AUTOSAR XML (schema 00052)
package /apd/AdaptiveApplicationSwComponentTypes
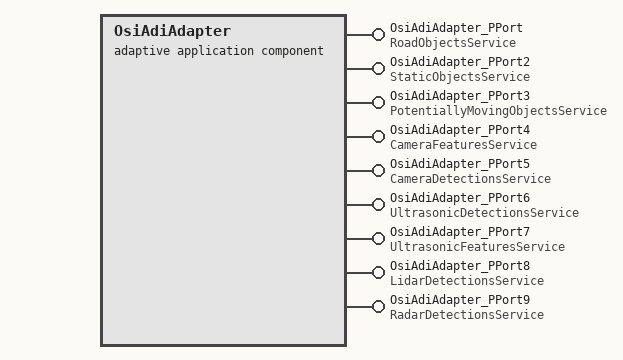
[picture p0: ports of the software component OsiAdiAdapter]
  adaptive application sw component type OsiAdiAdapter
    9 x provide port:
      OsiAdiAdapter_PPort: provided-interface=RoadObjectsService
      OsiAdiAdapter_PPort2: provided-interface=StaticObjectsService
      OsiAdiAdapter_PPort3: provided-interface=PotentiallyMovingObjectsService
      OsiAdiAdapter_PPort4: provided-interface=CameraFeaturesService
      OsiAdiAdapter_PPort5: provided-interface=CameraDetectionsService
      OsiAdiAdapter_PPort6: provided-interface=UltrasonicDetectionsService
      OsiAdiAdapter_PPort7: provided-interface=UltrasonicFeaturesService
      OsiAdiAdapter_PPort8: provided-interface=LidarDetectionsService
      OsiAdiAdapter_PPort9: provided-interface=RadarDetectionsService
package /apd/Executables
  executable OsiAdiAdapter: category=APPLICATION_LEVEL, minimum-timer-granularity=1000
    root sw component prototype OsiAdiAdapter: application-type=OsiAdiAdapter
